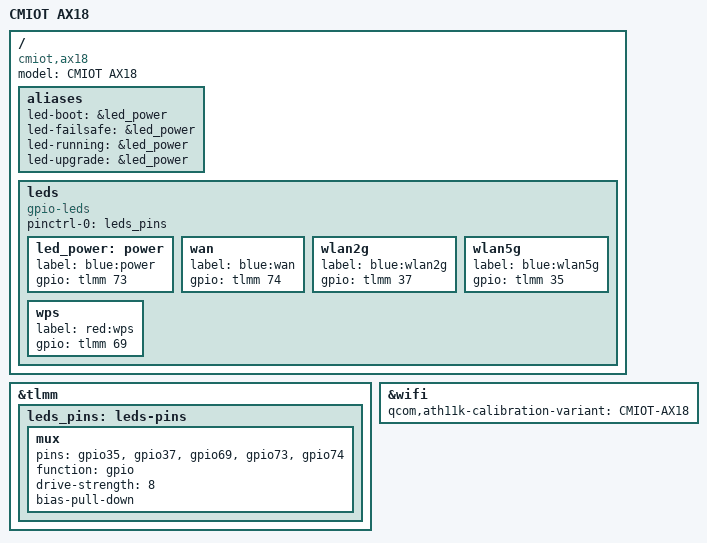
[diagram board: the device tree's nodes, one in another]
// SPDX-License-Identifier: GPL-2.0-or-later OR MIT

/dts-v1/;

#include "ipq6000-cmiot.dtsi"

/ {
	model = "CMIOT AX18";
	compatible = "cmiot,ax18", "qcom,ipq6018";

	aliases {
		led-boot = &led_power;
		led-failsafe = &led_power;
		led-running = &led_power;
		led-upgrade = &led_power;
	};

	leds {
		compatible = "gpio-leds";
		pinctrl-0 = <&leds_pins>;
		pinctrl-names = "default";

		led_power: power {
			label = "blue:power";
			gpio = <&tlmm 73 GPIO_ACTIVE_HIGH>;
		};

		wan {
			label = "blue:wan";
			gpio = <&tlmm 74 GPIO_ACTIVE_HIGH>;
		};

		wlan2g {
			label = "blue:wlan2g";
			gpio = <&tlmm 37 GPIO_ACTIVE_HIGH>;
		};

		wlan5g {
			label = "blue:wlan5g";
			gpio = <&tlmm 35 GPIO_ACTIVE_HIGH>;
		};

		wps {
			label = "red:wps";
			gpio = <&tlmm 69 GPIO_ACTIVE_HIGH>;
		};
	};
};

&tlmm {
	leds_pins: leds-pins {
		mux {
			pins = "gpio35", "gpio37", "gpio69", "gpio73", "gpio74";
			function = "gpio";
			drive-strength = <8>;
			bias-pull-down;
		};
	};
};

&wifi {
	qcom,ath11k-calibration-variant = "CMIOT-AX18";
};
